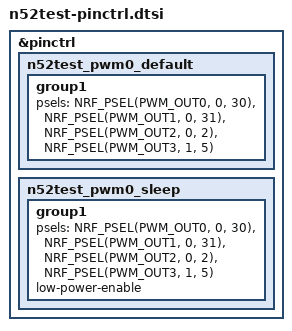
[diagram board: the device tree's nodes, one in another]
/*
 * Copyright (c) 2026 The ZMK Contributors
 * SPDX-License-Identifier: MIT
 */

&pinctrl {
    n52test_pwm0_default: n52test_pwm0_default {
        group1 {
            psels = <NRF_PSEL(PWM_OUT0, 0, 30)>,
                    <NRF_PSEL(PWM_OUT1, 0, 31)>,
                    <NRF_PSEL(PWM_OUT2, 0, 2)>,
                    <NRF_PSEL(PWM_OUT3, 1, 5)>;
        };
    };

    n52test_pwm0_sleep: n52test_pwm0_sleep {
        group1 {
            psels = <NRF_PSEL(PWM_OUT0, 0, 30)>,
                    <NRF_PSEL(PWM_OUT1, 0, 31)>,
                    <NRF_PSEL(PWM_OUT2, 0, 2)>,
                    <NRF_PSEL(PWM_OUT3, 1, 5)>;
            low-power-enable;
        };
    };
};
